# STM32U585 register map
File version: 2.2
CPU: CM33 r0p1, little endian, MPU, FPU, 4 interrupt priority bits
Registers are 32-bit, read-write, reset 0x0 unless marked. A register's access mark holds for its fields unless they carry their own. Offsets are from the block's base; [hi:lo] are bit positions; {n}, {i} and the like mark numbered series.

## GTZC2_MPCBB4
Base 0x46023800
Same registers: SEC_GTZC2_MPCBB4 0x56023800
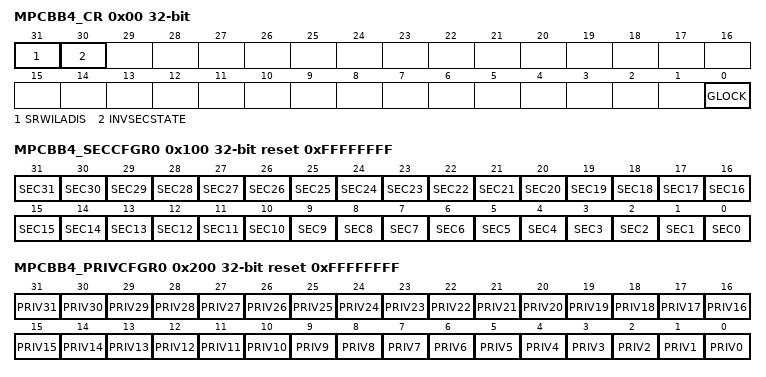
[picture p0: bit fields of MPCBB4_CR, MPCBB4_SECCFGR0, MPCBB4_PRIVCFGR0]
0x00 MPCBB4_CR — MPCBB control register
  [31] SRWILADIS — secure read/write illegal access disable
  [30] INVSECSTATE — SRAMx clocks security state
  [0] GLOCK — lock the control register of the MPCBB until next reset
0x10 MPCBB4_CFGLOCK — GTZC2 SRAM4 MPCBB configuration lock register
  [0] SPLCK0 — Security/privilege configuration lock for super-block 0
0x100 MPCBB4_SECCFGR0 reset 0xFFFFFFFF — MPCBB security configuration for super-block 0 register
  [n] SEC{n} (n=0..31)
0x200 MPCBB4_PRIVCFGR0 reset 0xFFFFFFFF — MPCBB privileged configuration for super-block 0 register
  [n] PRIV{n} (n=0..31)

## GTZC2_TZSC
Base 0x46023000
Same registers: SEC_GTZC2_TZSC 0x56023000
0x00 TZSC_CR — TZSC control register
  [0] LCK — lock the configuration of GTZC1_TZSC_SECCFGRx and GTZC1_TZSC_PRIVCFGRx
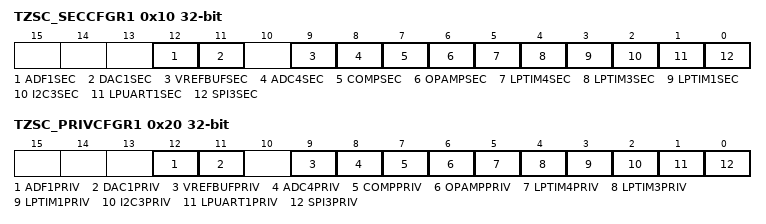
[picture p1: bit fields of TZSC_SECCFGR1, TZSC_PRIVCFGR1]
0x10 TZSC_SECCFGR1 — TZSC secure configuration register 1
  [12] ADF1SEC — secure access mode for ADF1
  [11] DAC1SEC — secure access mode for DAC1
  [9] VREFBUFSEC — secure access mode for VREFBUF
  [8] ADC4SEC — secure access mode for ADC4
  [7] COMPSEC — secure access mode for COMP
  [6] OPAMPSEC — secure access mode for OPAMP
  [5] LPTIM4SEC — secure access mode for LPTIM4
  [4] LPTIM3SEC — secure access mode for LPTIM3
  [3] LPTIM1SEC — secure access mode for LPTIM1
  [2] I2C3SEC — secure access mode for I2C3
  [1] LPUART1SEC — secure access mode for LPUART1
  [0] SPI3SEC — secure access mode for SPI3
0x20 TZSC_PRIVCFGR1 — TZSC privilege configuration register 1
  [12] ADF1PRIV — privileged access mode for ADF1
  [11] DAC1PRIV — privileged access mode for DAC1
  [9] VREFBUFPRIV — privileged access mode for VREFBUF
  [8] ADC4PRIV — privileged access mode for ADC4
  [7] COMPPRIV — privileged access mode for COMP
  [6] OPAMPPRIV — privileged access mode for OPAMP
  [5] LPTIM4PRIV — privileged access mode for LPTIM4
  [4] LPTIM3PRIV — privileged access mode for LPTIM3
  [3] LPTIM1PRIV — privileged access mode for LPTIM1
  [2] I2C3PRIV — privileged access mode for I2C3
  [1] LPUART1PRIV — privileged access mode for LPUART1
  [0] SPI3PRIV — privileged access mode for SPI3

## TIM16 — General purpose timers
Base 0x40014400
Same registers: TIM17 0x40014800, SEC_TIM16 0x50014400, SEC_TIM17 0x50014800
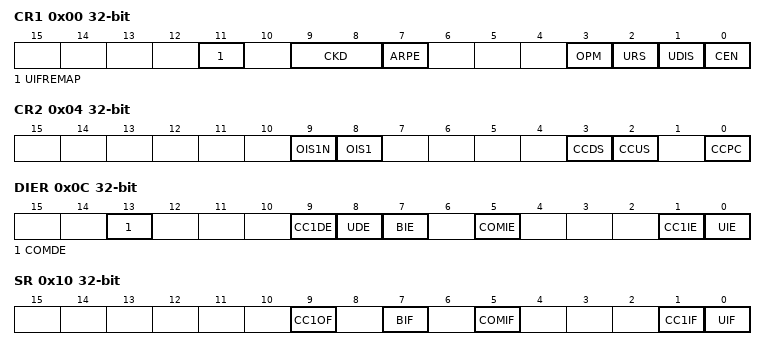
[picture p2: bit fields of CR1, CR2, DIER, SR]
0x00 CR1 — control register 1
  [11] UIFREMAP — UIF status bit remapping
  [9:8] CKD — Clock division
  [7] ARPE — Auto-reload preload enable
  [3] OPM — One pulse mode
  [2] URS — Update request source
  [1] UDIS — Update disable
  [0] CEN — Counter enable
0x04 CR2 — control register 2
  [9] OIS1N — Output Idle state 1
  [8] OIS1 — Output Idle state 1
  [3] CCDS — Capture/compare DMA
  [2] CCUS — Capture/compare control update
  [0] CCPC — Capture/compare preloaded
0x0C DIER — DMA/interrupt enable register
  [13] COMDE — COM DMA request enable
  [9] CC1DE — Capture/Compare 1 DMA request enable
  [8] UDE — Update DMA request enable
  [7] BIE — Break interrupt enable
  [5] COMIE — COM interrupt enable
  [1] CC1IE — Capture/Compare 1 interrupt enable
  [0] UIE — Update interrupt enable
0x10 SR — status register
  [9] CC1OF
  [7] BIF — Break interrupt flag
  [5] COMIF — COM interrupt flag
  [1] CC1IF — Capture/Compare 1 interrupt flag
  [0] UIF — Update interrupt flag
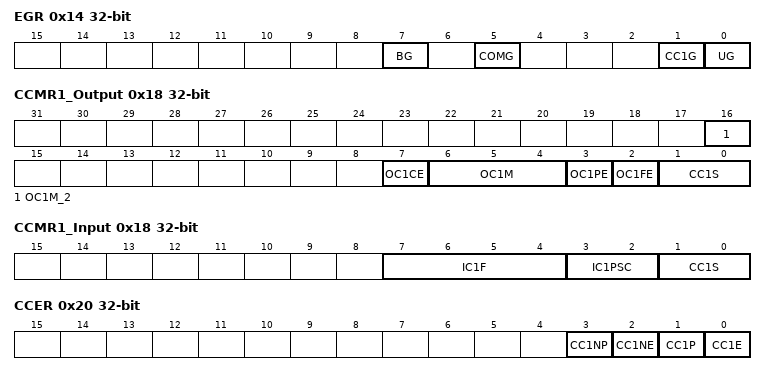
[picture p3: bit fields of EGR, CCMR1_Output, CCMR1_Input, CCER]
0x14 EGR wo — event generation register
  [7] BG — Break generation
  [5] COMG — Capture/Compare control update
  [1] CC1G — Capture/compare 1
  [0] UG — Update generation
0x18 CCMR1_Output — capture/compare mode register (output
  [16] OC1M_2 — Output Compare 1 mode
  [7] OC1CE — Output Compare 1 clear enable
  [6:4] OC1M — Output Compare 1 mode
  [3] OC1PE — Output Compare 1 preload
  [2] OC1FE — Output Compare 1 fast
  [1:0] CC1S — Capture/Compare 1
0x18 CCMR1_Input (alternate view of CCMR1_Output) — capture/compare mode register 1 (input
  [7:4] IC1F — Input capture 1 filter
  [3:2] IC1PSC — Input capture 1 prescaler
  [1:0] CC1S — Capture/Compare 1
0x20 CCER — capture/compare enable
  [3] CC1NP — Capture/Compare 1 output
  [2] CC1NE — Capture/Compare 1 complementary output
  [1] CC1P — Capture/Compare 1 output
  [0] CC1E — Capture/Compare 1 output
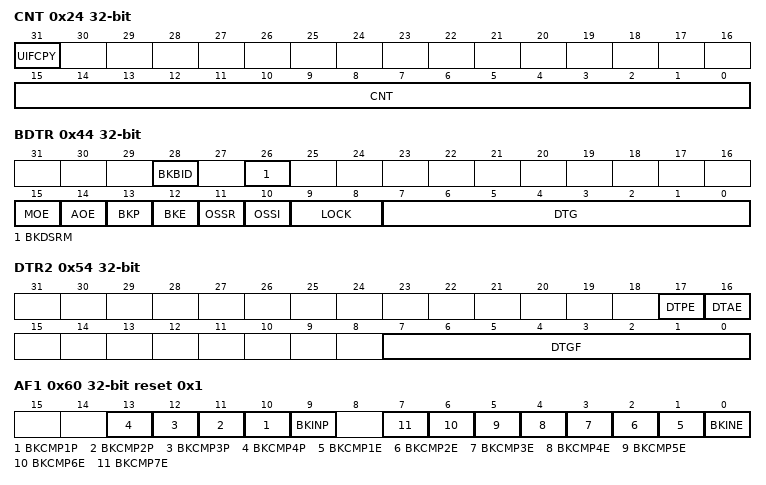
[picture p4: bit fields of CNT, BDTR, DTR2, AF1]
0x24 CNT access per field — counter
  [31] UIFCPY ro — UIF Copy
  [15:0] CNT rw
0x28 PSC — prescaler
  [15:0] PSC — Prescaler value
0x2C ARR reset 0xFFFF — auto-reload register
  [19:0] ARR — Auto-reload value
0x30 RCR — repetition counter register
  [7:0] REP — Repetition counter value
0x34 CCR1 — capture/compare register 1
  [19:0] CCR1 — Capture/Compare 1 value
0x44 BDTR — break and dead-time register
  [28] BKBID — Break Bidirectional
  [26] BKDSRM — Break Disarm
  [15] MOE — Main output enable
  [14] AOE — Automatic output enable
  [13] BKP — Break polarity
  [12] BKE — Break enable
  [11] OSSR — Off-state selection for Run
  [10] OSSI — Off-state selection for Idle
  [9:8] LOCK — Lock configuration
  [7:0] DTG — Dead-time generator setup
0x54 DTR2 — timer deadtime register 2
  [17] DTPE — Deadtime preload enable
  [16] DTAE — Deadtime asymmetric enable
  [7:0] DTGF — Deadtime asymmetric enable
0x5C TISEL — TIM17 option register 1
  [3:0] TI1SEL — selects tim_ti1_in[0..15] input
0x60 AF1 reset 0x1 — alternate function register 1
  [n+9] BKCMP{n}P (n=1..4) — tim_brk_cmp{n} input polarity
  [9] BKINP — TIMx_BKIN input polarity
  [n] BKCMP{n}E (n=1..7) — tim_brk_cmp{n} enable
  [0] BKINE — TIMx_BKIN input enable
0x64 AF2 reset 0x1 — alternate function register 2
  [18:16] OCRSEL — tim_ocref_clr source selection
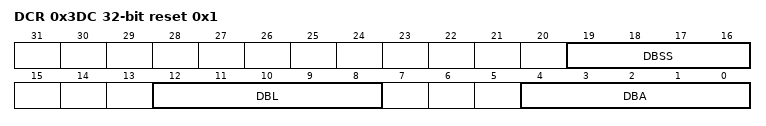
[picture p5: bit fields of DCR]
0x3DC DCR reset 0x1 — DMA control register
  [19:16] DBSS — DMA burst source selection
  [12:8] DBL — DMA burst length
  [4:0] DBA — DMA base address
0x3E0 DMAR reset 0x1 — TIM17 option register 1
  [31:0] DMAB — DMA register for burst accesses
